# STM32U375 register map
File version: 1.0
CPU: CM33 r0p1, little endian, MPU, FPU, 4 interrupt priority bits
Registers are 32-bit, read-write, reset 0x0 unless marked. A register's access mark holds for its fields unless they carry their own. Offsets are from the block's base; [hi:lo] are bit positions; {n}, {i} and the like mark numbered series.

## CRS — CRS address block description
Base 0x40006000
Same registers: SEC_CRS 0x50006000
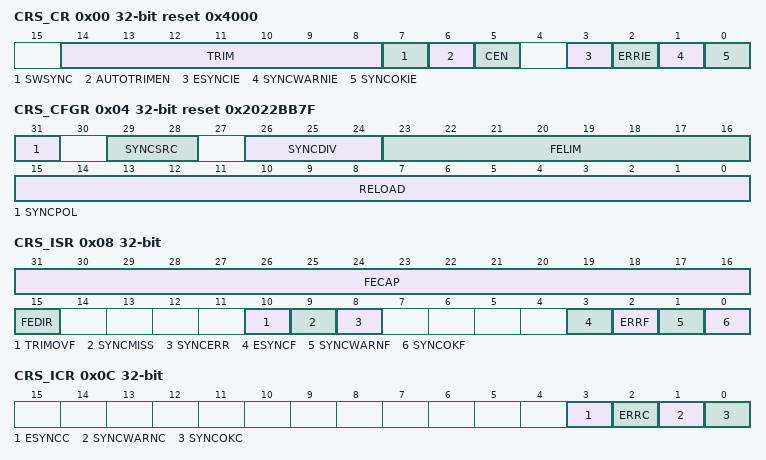
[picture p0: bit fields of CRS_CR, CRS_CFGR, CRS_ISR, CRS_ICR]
0x00 CRS_CR reset 0x4000 — CRS control register
  [14:8] TRIM — HSI48 oscillator smooth trimming
  [7] SWSYNC — Generate software SYNC event
    0=No action; 1=A software SYNC event is generated
  [6] AUTOTRIMEN — Automatic trimming enable
    0=Automatic trimming disabled, TRIM bits can be adjusted by the user; 1=Automatic trimming enabled, TRIM bits are read-only and under hardware control
  [5] CEN — Frequency error counter enable
    0=Frequency error counter disabled; 1=Frequency error counter enabled
  [3] ESYNCIE — Expected SYNC interrupt enable
    0=Expected SYNC (ESYNCF) interrupt disabled; 1=Expected SYNC (ESYNCF) interrupt enabled
  [2] ERRIE — Synchronization or trimming error interrupt enable
    0=Synchronization or trimming error (ERRF) interrupt disabled; 1=Synchronization or trimming error (ERRF) interrupt enabled
  [1] SYNCWARNIE — SYNC warning interrupt enable
    0=SYNC warning (SYNCWARNF) interrupt disabled; 1=SYNC warning (SYNCWARNF) interrupt enabled
  [0] SYNCOKIE — SYNC event OK interrupt enable
    0=SYNC event OK (SYNCOKF) interrupt disabled; 1=SYNC event OK (SYNCOKF) interrupt enabled
0x04 CRS_CFGR reset 0x2022BB7F — CRS configuration register
  [31] SYNCPOL — SYNC polarity selection
    0=SYNC active on rising edge (default); 1=SYNC active on falling edge
  [29:28] SYNCSRC — SYNC signal source selection
    {v}=crs_sync_in_{v+1} selected as SYNC signal source (v=0..3)
  [26:24] SYNCDIV — SYNC divider
    0=SYNC not divided (default); 1=SYNC divided by 2; 2=SYNC divided by 4; 3=SYNC divided by 8; 4=SYNC divided by 16; 5=SYNC divided by 32; 6=SYNC divided by 64; 7=SYNC divided by 128
  [23:16] FELIM — Frequency error limit
  [15:0] RELOAD — Counter reload value
0x08 CRS_ISR ro — CRS interrupt and status register
  [31:16] FECAP — Frequency error capture
  [15] FEDIR — Frequency error direction
    0=Up-counting direction, the actual frequency is above the target; 1=Down-counting direction, the actual frequency is below the target
  [10] TRIMOVF — Trimming overflow or underflow
    0=No trimming error signaled; 1=Trimming error signaled
  [9] SYNCMISS — SYNC missed
    0=No SYNC missed error signaled; 1=SYNC missed error signaled
  [8] SYNCERR — SYNC error
    0=No SYNC error signaled; 1=SYNC error signaled
  [3] ESYNCF — Expected SYNC flag
    0=No expected SYNC signaled; 1=Expected SYNC signaled
  [2] ERRF — Error flag
    0=No synchronization or trimming error signaled; 1=Synchronization or trimming error signaled
  [1] SYNCWARNF — SYNC warning flag
    0=No SYNC warning signaled; 1=SYNC warning signaled
  [0] SYNCOKF — SYNC event OK flag
    0=No SYNC event OK signaled; 1=SYNC event OK signaled
0x0C CRS_ICR — CRS interrupt flag clear register
  [3] ESYNCC — Expected SYNC clear flag
  [2] ERRC — Error clear flag
  [1] SYNCWARNC — SYNC warning clear flag
  [0] SYNCOKC — SYNC event OK clear flag

## DLYBSD1 — DLYB Address block
Base 0x420C8400
Same registers: DLYBOS1 0x420CF000, SEC_DLYBSD1 0x520C8400, SEC_DLYBOS1 0x520CF000
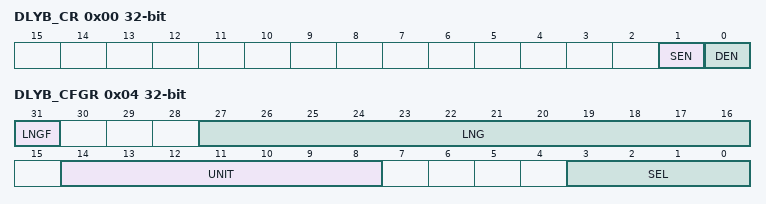
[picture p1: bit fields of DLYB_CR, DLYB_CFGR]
0x00 DLYB_CR — DLYB control register
  [1] SEN — 0: Sampler length and register access to UNIT[6:0] and SEL[3:0] disabled, output clock enabled. 1: Sampler length and register access to UNIT[6:0] and SEL[3:0] enabled, output clock disabled.
    0=Sampler length and register access to UNIT[6:0] and SEL[3:0] disabled, output clock enabled; 1=Sampler length and register access to UNIT[6:0] and SEL[3:0] enabled, output clock disabled
  [0] DEN — 0: DLYB disabled. 1: DLYB enabled.
    0=DLYB disabled; 1=DLYB enabled
0x04 DLYB_CFGR access per field — DLYB configuration register
  [31] LNGF ro — This flag indicates when the delay line length value contained in LNG[11:0] is valid after UNIT[6:0] bits changed. 0: Length value in LNG is not valid. 1: Length value in LNG is valid.
    0=Length value in LNG is not valid; 1=Length value in LNG is valid
  [27:16] LNG ro — These bits reflect the 12 unit delay values sampled at the rising edge of the input clock. The value is only valid when LNGF = 1.
  [14:8] UNIT rw — These bits can only be written when SEN = 1. Unit delay = initial delay + UNIT[6:0] x delay step
  [3:0] SEL rw — These bits can only be written when SEN = 1. Output clock phase = input clock + SEL[3:0] x unit delay
